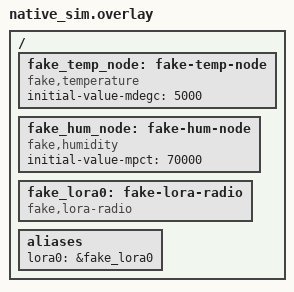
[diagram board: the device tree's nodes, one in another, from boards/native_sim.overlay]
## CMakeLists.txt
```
# SPDX-License-Identifier: Apache-2.0

cmake_minimum_required(VERSION 3.20.0)

find_package(Zephyr REQUIRED HINTS $ENV{ZEPHYR_BASE})
project(sensor_node VERSION 0.1.0)

target_sources(app PRIVATE src/main.c)

# Expose the shared include/ directory so weather_messages.h is reachable.
target_include_directories(app PRIVATE ${CMAKE_SOURCE_DIR}/../../include)
```

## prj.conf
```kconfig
# Sensor-node application configuration.
# Lighter than gateway: no auto-publish timer, no registry (optional).

CONFIG_ZBUS=y
CONFIG_ZBUS_CHANNEL_NAME=y
CONFIG_ZBUS_OBSERVER_NAME=y
CONFIG_ZBUS_RUNTIME_OBSERVERS=y

CONFIG_SHELL=y
CONFIG_SHELL_BACKEND_SERIAL=y

CONFIG_LOG=y
CONFIG_LOG_DEFAULT_LEVEL=3

CONFIG_SENSOR_EVENT=y
CONFIG_SENSOR_EVENT_LOG=y
CONFIG_SENSOR_TRIGGER=y
CONFIG_SENSOR_REGISTRY=y
CONFIG_FAKE_SENSORS=y
CONFIG_FAKE_SENSORS_SHELL=y
CONFIG_FAKE_TEMPERATURE_UID_BASE=0x0021
CONFIG_FAKE_HUMIDITY_UID_BASE=0x0022
CONFIG_PIPE_PUBLISHER=y

# LoRa TX subsystem
CONFIG_LORA=y
CONFIG_LORA_RADIO=y
CONFIG_REMOTE_SENSOR=y
CONFIG_LORA_RADIO_FAKE=y
CONFIG_LORA_NODE=y
CONFIG_PSA_CRYPTO=y
CONFIG_PSA_CRYPTO_PROVIDER_MBEDTLS=y
CONFIG_CONFIG_CMD=y
CONFIG_SENSOR_NODE_TX=y

# Dev node identity: fixed key so the sim node can encrypt. NEVER in production.
CONFIG_LORA_NODE_DEV_KEY="000102030405060708090a0b0c0d0e0f"
CONFIG_LORA_NODE_DEV_NODE_ID=1
CONFIG_SETTINGS=y
```

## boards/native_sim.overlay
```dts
/*
 * SPDX-License-Identifier: Apache-2.0
 *
 * Sensor-node DT overlay for native_sim.
 *
 * Defines two fake sensors for node_0:
 *   - One temperature sensor
 *   - One humidity sensor
 *
 * Sensor UIDs are assigned at build time via Kconfig:
 *   CONFIG_FAKE_TEMPERATURE_UID_BASE (default 0x0021)
 *   CONFIG_FAKE_HUMIDITY_UID_BASE (default 0x0022)
 */

/ {
	fake_temp_node: fake-temp-node {
		compatible = "fake,temperature";
		initial-value-mdegc = <5000>;
		status = "okay";
	};

	fake_hum_node: fake-hum-node {
		compatible = "fake,humidity";
		initial-value-mpct = <70000>;
		status = "okay";
	};

	fake_lora0: fake-lora-radio {
		compatible = "fake,lora-radio";
		status = "okay";
	};

	aliases {
		lora0 = &fake_lora0;
	};
};
```

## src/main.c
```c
/* SPDX-License-Identifier: Apache-2.0 */
/**
 * @file main.c (sensor-node)
 * @brief Sensor-node application entry point.
 *
 * Per ADR-008 RULE 4: main.c registers the log module and sleeps forever.
 * All application logic is initialised via SYS_INIT callbacks in library
 * modules, activated by the Kconfig options in prj.conf.
 *
 * Sensor event logging is provided by lib/sensor_event_log/
 * (CONFIG_SENSOR_EVENT_LOG=y in prj.conf).
 */

#include <zephyr/kernel.h>
#include <zephyr/logging/log.h>

LOG_MODULE_REGISTER(sensor_node, LOG_LEVEL_INF);

int main(void)
{
	LOG_INF("weather-station sensor-node v0.1.0");
	k_sleep(K_FOREVER);
	return 0;
}
```
